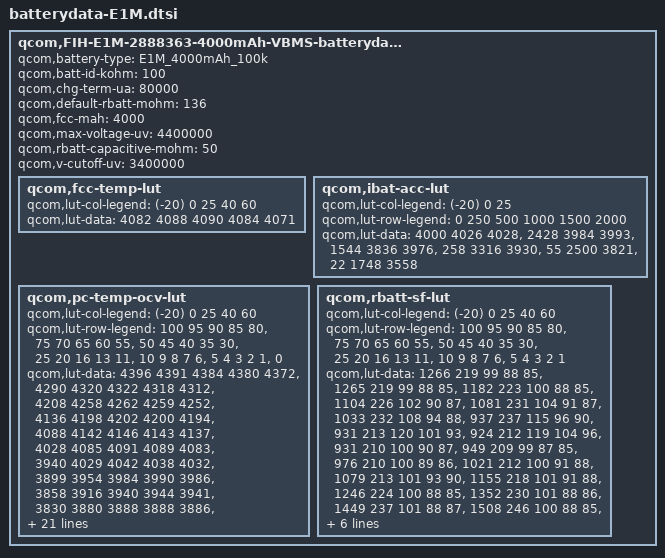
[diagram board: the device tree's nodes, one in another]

qcom,FIH-E1M-2888363-4000mAh-VBMS-batterydata {
	qcom,battery-type = "E1M_4000mAh_100k";
	qcom,batt-id-kohm = <100>;
	qcom,chg-term-ua = <80000>;
	qcom,default-rbatt-mohm = <136>;
	qcom,fcc-mah = <4000>;
	qcom,max-voltage-uv = <4400000>;
	qcom,rbatt-capacitive-mohm = <50>;
	qcom,v-cutoff-uv = <3400000>;

	qcom,fcc-temp-lut {
		qcom,lut-col-legend = <(-20) 0 25 40 60>;
		qcom,lut-data = <4082 4088 4090 4084 4071>;
	};

	qcom,ibat-acc-lut {
		qcom,lut-col-legend = <(-20) 0 25>;
		qcom,lut-row-legend = <0 250 500 1000 1500 2000>;
		qcom,lut-data = <4000 4026 4028>,
				<2428 3984 3993>,
				<1544 3836 3976>,
				<258 3316 3930>,
				<55 2500 3821>,
				<22 1748 3558>;
	};

	qcom,pc-temp-ocv-lut {
		qcom,lut-col-legend = <(-20) 0 25 40 60>;
		qcom,lut-row-legend = <100 95 90 85 80>,
					<75 70 65 60 55>,
					<50 45 40 35 30>,
					<25 20 16 13 11>,
					<10 9 8 7 6>,
					<5 4 3 2 1>,
					<0>;
		qcom,lut-data = <4396 4391 4384 4380 4372>,
				<4290 4320 4322 4318 4312>,
				<4208 4258 4262 4259 4252>,
				<4136 4198 4202 4200 4194>,
				<4088 4142 4146 4143 4137>,
				<4028 4085 4091 4089 4083>,
				<3940 4029 4042 4038 4032>,
				<3899 3954 3984 3990 3986>,
				<3858 3916 3940 3944 3941>,
				<3830 3880 3888 3888 3886>,
				<3808 3849 3854 3854 3852>,
				<3793 3822 3828 3828 3825>,
				<3779 3798 3806 3806 3804>,
				<3764 3780 3788 3788 3786>,
				<3748 3766 3772 3770 3764>,
				<3730 3752 3756 3748 3736>,
				<3710 3734 3737 3728 3715>,
				<3690 3717 3717 3708 3694>,
				<3670 3707 3696 3688 3676>,
				<3654 3700 3690 3682 3670>,
				<3644 3697 3688 3680 3668>,
				<3632 3693 3686 3679 3668>,
				<3619 3688 3684 3677 3666>,
				<3603 3682 3682 3674 3662>,
				<3584 3670 3674 3666 3651>,
				<3558 3646 3650 3642 3621>,
				<3527 3610 3607 3598 3574>,
				<3482 3554 3548 3540 3514>,
				<3413 3474 3464 3459 3430>,
				<3284 3344 3336 3334 3297>,
				<3000 3000 3000 3000 3000>;
	};

	qcom,rbatt-sf-lut {
		qcom,lut-col-legend = <(-20) 0 25 40 60>;
		qcom,lut-row-legend = <100 95 90 85 80>,
					<75 70 65 60 55>,
					<50 45 40 35 30>,
					<25 20 16 13 11>,
					<10 9 8 7 6>,
					<5 4 3 2 1>;
		qcom,lut-data = <1266 219 99 88 85>,
				<1265 219 99 88 85>,
				<1182 223 100 88 85>,
				<1104 226 102 90 87>,
				<1081 231 104 91 87>,
				<1033 232 108 94 88>,
				<937 237 115 96 90>,
				<931 213 120 101 93>,
				<924 212 119 104 96>,
				<931 210 100 90 87>,
				<949 209 99 87 85>,
				<976 210 100 89 86>,
				<1021 212 100 91 88>,
				<1079 213 101 93 90>,
				<1155 218 101 91 88>,
				<1246 224 100 88 85>,
				<1352 230 101 88 86>,
				<1449 237 101 88 87>,
				<1508 246 100 88 85>,
				<1496 253 100 88 86>,
				<1554 262 101 90 88>,
				<1642 274 103 93 90>,
				<1768 286 106 96 94>,
				<1949 301 110 99 99>,
				<2180 317 113 101 98>,
				<2478 330 109 96 90>,
				<2899 351 107 93 91>,
				<3512 390 110 95 93>,
				<4601 460 115 99 98>,
				<9203 632 142 121 141>;
	};
};
